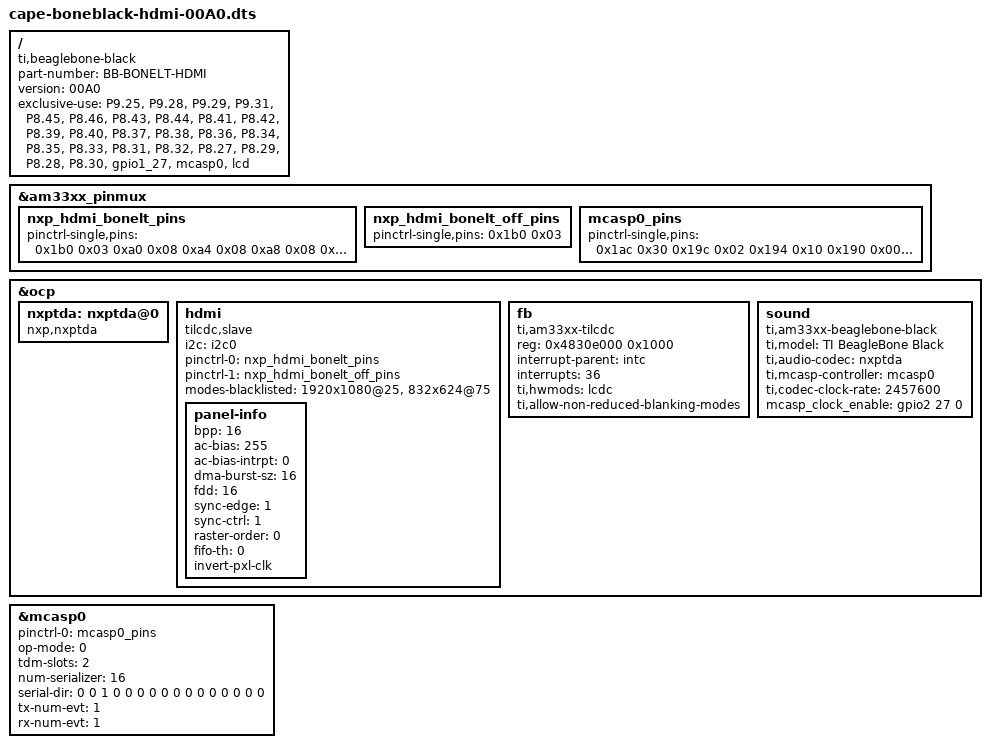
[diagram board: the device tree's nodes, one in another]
/*
* Copyright (C) 2012 Texas Instruments Incorporated - http://www.ti.com/
*
* This program is free software; you can redistribute it and/or modify
* it under the terms of the GNU General Public License version 2 as
* published by the Free Software Foundation.
*/
/dts-v1/;
/plugin/;

/ {
	compatible = "ti,beaglebone-black";
	part-number = "BB-BONELT-HDMI";
	version = "00A0";

	/* state the resources this cape uses */
	exclusive-use =
		/* the pin header uses */
		"P9.25",	/* mcasp0: mcasp0_ahclkx */
		"P9.28",	/* mcasp0: mcasp0_axr2 */
		"P9.29",	/* mcasp0: mcasp0_fsx */
		"P9.31",	/* mcasp0: mcasp0_aclkx */
		"P8.45",	/* lcd: lcd_data0 */
		"P8.46",	/* lcd: lcd_data1 */
		"P8.43",	/* lcd: lcd_data2 */
		"P8.44",	/* lcd: lcd_data3 */
		"P8.41",	/* lcd: lcd_data4 */
		"P8.42",	/* lcd: lcd_data5 */
		"P8.39",	/* lcd: lcd_data6 */
		"P8.40",	/* lcd: lcd_data7 */
		"P8.37",	/* lcd: lcd_data8 */
		"P8.38",	/* lcd: lcd_data9 */
		"P8.36",	/* lcd: lcd_data10 */
		"P8.34",	/* lcd: lcd_data11 */
		"P8.35",	/* lcd: lcd_data12 */
		"P8.33",	/* lcd: lcd_data13 */
		"P8.31",	/* lcd: lcd_data14 */
		"P8.32",	/* lcd: lcd_data15 */
		"P8.27",	/* lcd: lcd_vsync */
		"P8.29",	/* lcd: lcd_hsync */
		"P8.28",	/* lcd: lcd_pclk */
		"P8.30",	/* lcd: lcd_ac_bias_en */
		/* the hardware IP uses */
		"gpio1_27",
		"mcasp0",
		"lcd";

	fragment@0 {
		target = <&am33xx_pinmux>;
		__overlay__ {
			nxp_hdmi_bonelt_pins: nxp_hdmi_bonelt_pins {
				pinctrl-single,pins = <
					0x1b0 0x03      /* xdma_event_intr0, OMAP_MUX_MODE3 | AM33XX_PIN_OUTPUT */
					0xa0 0x08       /* lcd_data0.lcd_data0, OMAP_MUX_MODE0 | AM33XX_PIN_OUTPUT | AM33XX_PULL_DISA */
					0xa4 0x08       /* lcd_data1.lcd_data1, OMAP_MUX_MODE0 | AM33XX_PIN_OUTPUT | AM33XX_PULL_DISA */
					0xa8 0x08       /* lcd_data2.lcd_data2, OMAP_MUX_MODE0 | AM33XX_PIN_OUTPUT | AM33XX_PULL_DISA */
					0xac 0x08       /* lcd_data3.lcd_data3, OMAP_MUX_MODE0 | AM33XX_PIN_OUTPUT | AM33XX_PULL_DISA */
					0xb0 0x08       /* lcd_data4.lcd_data4, OMAP_MUX_MODE0 | AM33XX_PIN_OUTPUT | AM33XX_PULL_DISA */
					0xb4 0x08       /* lcd_data5.lcd_data5, OMAP_MUX_MODE0 | AM33XX_PIN_OUTPUT | AM33XX_PULL_DISA */
					0xb8 0x08       /* lcd_data6.lcd_data6, OMAP_MUX_MODE0 | AM33XX_PIN_OUTPUT | AM33XX_PULL_DISA */
					0xbc 0x08       /* lcd_data7.lcd_data7, OMAP_MUX_MODE0 | AM33XX_PIN_OUTPUT | AM33XX_PULL_DISA */
					0xc0 0x08       /* lcd_data8.lcd_data8, OMAP_MUX_MODE0 | AM33XX_PIN_OUTPUT | AM33XX_PULL_DISA */
					0xc4 0x08       /* lcd_data9.lcd_data9, OMAP_MUX_MODE0 | AM33XX_PIN_OUTPUT | AM33XX_PULL_DISA */
					0xc8 0x08       /* lcd_data10.lcd_data10, OMAP_MUX_MODE0 | AM33XX_PIN_OUTPUT | AM33XX_PULL_DISA */
					0xcc 0x08       /* lcd_data11.lcd_data11, OMAP_MUX_MODE0 | AM33XX_PIN_OUTPUT | AM33XX_PULL_DISA */
					0xd0 0x08       /* lcd_data12.lcd_data12, OMAP_MUX_MODE0 | AM33XX_PIN_OUTPUT | AM33XX_PULL_DISA */
					0xd4 0x08       /* lcd_data13.lcd_data13, OMAP_MUX_MODE0 | AM33XX_PIN_OUTPUT | AM33XX_PULL_DISA */
					0xd8 0x08       /* lcd_data14.lcd_data14, OMAP_MUX_MODE0 | AM33XX_PIN_OUTPUT | AM33XX_PULL_DISA */
					0xdc 0x08       /* lcd_data15.lcd_data15, OMAP_MUX_MODE0 | AM33XX_PIN_OUTPUT | AM33XX_PULL_DISA */
					0xe0 0x00       /* lcd_vsync.lcd_vsync, OMAP_MUX_MODE0 | AM33XX_PIN_OUTPUT */
					0xe4 0x00       /* lcd_hsync.lcd_hsync, OMAP_MUX_MODE0 | AM33XX_PIN_OUTPUT */
					0xe8 0x00       /* lcd_pclk.lcd_pclk, OMAP_MUX_MODE0 | AM33XX_PIN_OUTPUT */
					0xec 0x00       /* lcd_ac_bias_en.lcd_ac_bias_en, OMAP_MUX_MODE0 | AM33XX_PIN_OUTPUT */
				>;
			};
			nxp_hdmi_bonelt_off_pins: nxp_hdmi_bonelt_off_pins {
				pinctrl-single,pins = <
					0x1b0 0x03      /* xdma_event_intr0, OMAP_MUX_MODE3 | AM33XX_PIN_OUTPUT */
				>;
			};

			mcasp0_pins: mcasp0_pins {
				pinctrl-single,pins = <
					0x1ac 0x30      /* mcasp0_ahclkx,       MODE0 | INPUT */
					0x19c 0x02	/* mcasp0_ahclkr, */
					0x194 0x10      /* mcasp0_fsx,         MODE0 | OUTPUT  */
					0x190 0x00      /* mcasp0_aclkr.mcasp0_aclkx,     MODE0 | OUTPUT_PULLDOWN */
					0x1a8 0x1f	/* mcasp0_axr1 GPIO1_27 | OUTPUT | PULLUP */
				>;
			};
		};
	};

	fragment@2 {
		target = <&ocp>;
		__overlay__ {

			/* avoid stupid warning */
			#address-cells = <1>;
			#size-cells = <1>;

			nxptda: nxptda@0 {
			       compatible = "nxp,nxptda";
			       status = "okay";
			};

			hdmi {
				compatible = "tilcdc,slave";
				i2c = <&i2c0>;
				pinctrl-names = "default", "off";
				pinctrl-0 = <&nxp_hdmi_bonelt_pins>;
				pinctrl-1 = <&nxp_hdmi_bonelt_off_pins>;

				modes-blacklisted =
					"1920x1080@25",
					"832x624@75";

				// Enable this when we figure out the modes
				//
				// modes-whitelisted =
				//	"1920x1080@24",
				//	"1280x720@50", "1280x720@60",
				//	"720x576@50","720x480@60";

				panel-info {
					bpp = <16>;
					ac-bias = <255>;
					ac-bias-intrpt = <0>;
					dma-burst-sz = <16>;
					fdd = <16>;
					sync-edge = <1>;
					sync-ctrl = <1>;
					raster-order = <0>;
					fifo-th = <0>;
					invert-pxl-clk;
				};
			};

			fb {
				compatible = "ti,am33xx-tilcdc";
				reg = <0x4830e000 0x1000>;
				interrupt-parent = <&intc>;
				interrupts = <36>;
				ti,hwmods = "lcdc";
				ti,allow-non-reduced-blanking-modes;
			};

		};
	};

	fragment@3 {
		target = <&mcasp0>;
		__overlay__ {
			pinctrl-names = "default";
			pinctrl-0 = <&mcasp0_pins>;

			status = "okay";

			op-mode = <0>;          /* MCASP_IIS_MODE */
			tdm-slots = <2>;
			num-serializer = <16>;
			serial-dir = <  /* 0: INACTIVE, 1: TX, 2: RX */
				0 0 1 0
				0 0 0 0
				0 0 0 0
				0 0 0 0
			>;
			tx-num-evt = <1>;
			rx-num-evt = <1>;
		};
	};

	fragment@4 {
		target = <&ocp>;
		__overlay__ {
			sound {
				compatible = "ti,am33xx-beaglebone-black";
				ti,model = "TI BeagleBone Black";
				ti,audio-codec = <&nxptda>;
				ti,mcasp-controller = <&mcasp0>;
				ti,codec-clock-rate = <2457600>;
				mcasp_clock_enable = <&gpio2 27 0>; /* BeagleBone Black Clk enable on GPIO1_27 */
			};
		};

	};

};
